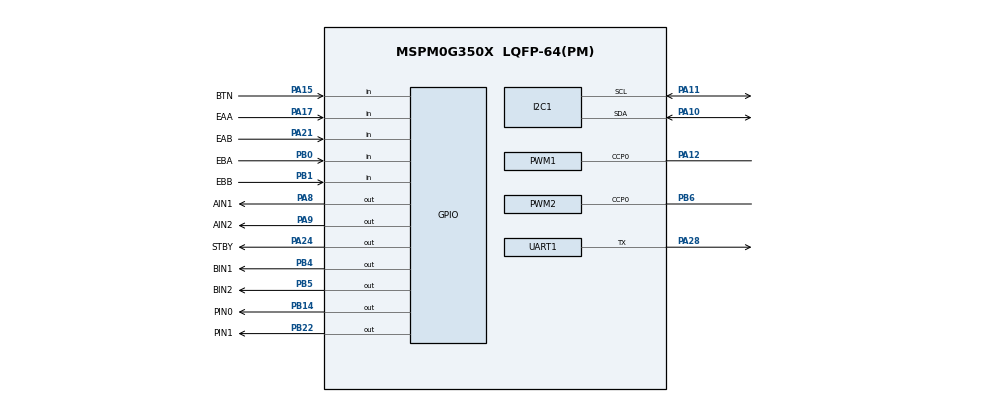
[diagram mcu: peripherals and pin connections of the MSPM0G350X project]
/**
 * @cliArgs --device "MSPM0G350X" --part "Default" --package "LQFP-64(PM)" --product "mspm0_sdk@2.10.00.04"
 * @versions {"tool":"1.26.2+4477"}
 */

/**
 * Import the modules used in this configuration.
 */
const ADC12  = scripting.addModule("/ti/driverlib/ADC12", {}, false);
const ADC121 = ADC12.addInstance();
const GPIO   = scripting.addModule("/ti/driverlib/GPIO", {}, false);
const GPIO1  = GPIO.addInstance();
const GPIO2  = GPIO.addInstance();
const GPIO3  = GPIO.addInstance();
const GPIO4  = GPIO.addInstance();

const I2C    = scripting.addModule("/ti/driverlib/I2C", {}, false);
const I2C1   = I2C.addInstance();
const PWM    = scripting.addModule("/ti/driverlib/PWM", {}, false);
const PWM1   = PWM.addInstance();
const PWM2   = PWM.addInstance();
const SYSCTL = scripting.addModule("/ti/driverlib/SYSCTL");
const UART   = scripting.addModule("/ti/driverlib/UART", {}, false);
const UART1  = UART.addInstance();
const VREF   = scripting.addModule("/ti/driverlib/VREF");

/**
 * Write custom configuration values to the imported modules.
 */
const divider9       = system.clockTree["UDIV"];
divider9.divideValue = 2;

const multiplier2         = system.clockTree["PLL_QDIV"];
multiplier2.multiplyValue = 4;

const mux8       = system.clockTree["HSCLKMUX"];
mux8.inputSelect = "HSCLKMUX_SYSPLL0";

ADC121.$name                      = "ADC12_0";
ADC121.repeatMode                 = true;
ADC121.adcMem0vref                = "VREF";
ADC121.adcMem0chansel             = "DL_ADC12_INPUT_CHAN_1";
ADC121.peripheral.$assign         = "ADC1";
ADC121.peripheral.adcPin1.$assign = "PA16";
ADC121.adcPin1Config.$name        = "ti_driverlib_gpio_GPIOPinGeneric4";

const Board = scripting.addModule("/ti/driverlib/Board", {}, false);

GPIO1.$name                         = "LED";
GPIO1.associatedPins.create(2);
GPIO1.associatedPins[0].$name       = "PIN0";
GPIO1.associatedPins[0].pin.$assign = "PB14";
GPIO1.associatedPins[1].$name       = "PIN1";
GPIO1.associatedPins[1].pin.$assign = "PB22";

GPIO2.$name                              = "DC_MOTOR_1";
GPIO2.associatedPins.create(5);
GPIO2.associatedPins[0].$name            = "AIN1";
GPIO2.associatedPins[0].pin.$assign      = "PA8";
GPIO2.associatedPins[1].$name            = "AIN2";
GPIO2.associatedPins[1].pin.$assign      = "PA9";
GPIO2.associatedPins[2].$name            = "STBY";
GPIO2.associatedPins[2].pin.$assign      = "PA24";
GPIO2.associatedPins[3].$name            = "EAA";
GPIO2.associatedPins[3].direction        = "INPUT";
GPIO2.associatedPins[3].interruptEn      = true;
GPIO2.associatedPins[3].polarity         = "RISE";
GPIO2.associatedPins[3].internalResistor = "PULL_UP";
GPIO2.associatedPins[3].pin.$assign      = "PA17";
GPIO2.associatedPins[4].$name            = "EAB";
GPIO2.associatedPins[4].direction        = "INPUT";
GPIO2.associatedPins[4].interruptEn      = true;
GPIO2.associatedPins[4].polarity         = "RISE";
GPIO2.associatedPins[4].internalResistor = "PULL_UP";
GPIO2.associatedPins[4].pin.$assign      = "PA21";

GPIO3.$name                              = "DC_MOTOR_2";
GPIO3.associatedPins.create(4);
GPIO3.associatedPins[0].$name            = "BIN1";
GPIO3.associatedPins[0].pin.$assign      = "PB4";
GPIO3.associatedPins[1].$name            = "BIN2";
GPIO3.associatedPins[1].pin.$assign      = "PB5";
GPIO3.associatedPins[2].$name            = "EBA";
GPIO3.associatedPins[2].polarity         = "RISE";
GPIO3.associatedPins[2].direction        = "INPUT";
GPIO3.associatedPins[2].interruptEn      = true;
GPIO3.associatedPins[2].internalResistor = "PULL_UP";
GPIO3.associatedPins[2].pin.$assign      = "PB0";
GPIO3.associatedPins[3].$name            = "EBB";
GPIO3.associatedPins[3].direction        = "INPUT";
GPIO3.associatedPins[3].polarity         = "RISE";
GPIO3.associatedPins[3].interruptEn      = true;
GPIO3.associatedPins[3].internalResistor = "PULL_UP";
GPIO3.associatedPins[3].pin.$assign      = "PB1";

GPIO4.$name                              = "BUTTON";
GPIO4.associatedPins[0].$name            = "BTN";
GPIO4.associatedPins[0].internalResistor = "PULL_UP";
GPIO4.associatedPins[0].direction        = "INPUT";
GPIO4.associatedPins[0].pin.$assign      = "PA15";

I2C1.$name                             = "OLED";
I2C1.advDigitalGlitchFilter            = "CLOCKS_1";
I2C1.advControllerRXFIFOTRIG           = "BYTES_8";
I2C1.advControllerTXFIFOTRIG           = "BYTES_7";
I2C1.enableDMAEvent1                   = false;
I2C1.enableDMAEvent2                   = false;
I2C1.basicEnableController             = true;
I2C1.peripheral.$assign                = "I2C1";
I2C1.peripheral.sdaPin.$assign         = "PA10";
I2C1.peripheral.sclPin.$assign         = "PA11";
I2C1.sdaPinConfig.hideOutputInversion  = scripting.forceWrite(false);
I2C1.sdaPinConfig.onlyInternalResistor = scripting.forceWrite(false);
I2C1.sdaPinConfig.passedPeripheralType = scripting.forceWrite("Digital");
I2C1.sdaPinConfig.$name                = "ti_driverlib_gpio_GPIOPinGeneric0";
I2C1.sdaPinConfig.enableConfig         = true;
I2C1.sdaPinConfig.internalResistor     = "PULL_UP";
I2C1.sclPinConfig.hideOutputInversion  = scripting.forceWrite(false);
I2C1.sclPinConfig.onlyInternalResistor = scripting.forceWrite(false);
I2C1.sclPinConfig.passedPeripheralType = scripting.forceWrite("Digital");
I2C1.sclPinConfig.$name                = "ti_driverlib_gpio_GPIOPinGeneric1";
I2C1.sclPinConfig.enableConfig         = true;
I2C1.sclPinConfig.internalResistor     = "PULL_UP";

PWM1.$name                              = "PWMA";
PWM1.timerStartTimer                    = true;
PWM1.ccIndex                            = [0];
PWM1.timerCount                         = 4000;
PWM1.pwmMode                            = "EDGE_ALIGN_UP";
PWM1.clockDivider                       = 2;
PWM1.PWM_CHANNEL_0.$name                = "ti_driverlib_pwm_PWMTimerCC1";
PWM1.ccp0PinConfig.direction            = scripting.forceWrite("OUTPUT");
PWM1.ccp0PinConfig.hideOutputInversion  = scripting.forceWrite(false);
PWM1.ccp0PinConfig.onlyInternalResistor = scripting.forceWrite(false);
PWM1.ccp0PinConfig.passedPeripheralType = scripting.forceWrite("Digital");
PWM1.ccp0PinConfig.$name                = "ti_driverlib_gpio_GPIOPinGeneric6";
PWM1.peripheral.$assign                 = "TIMG0";
PWM1.peripheral.ccp0Pin.$assign         = "PA12";

PWM2.timerStartTimer                    = true;
PWM2.timerCount                         = 4000;
PWM2.pwmMode                            = "EDGE_ALIGN_UP";
PWM2.$name                              = "PWMB";
PWM2.ccIndex                            = [0];
PWM2.clockDivider                       = 2;
PWM2.PWM_CHANNEL_0.$name                = "ti_driverlib_pwm_PWMTimerCC4";
PWM2.ccp0PinConfig.direction            = scripting.forceWrite("OUTPUT");
PWM2.ccp0PinConfig.hideOutputInversion  = scripting.forceWrite(false);
PWM2.ccp0PinConfig.onlyInternalResistor = scripting.forceWrite(false);
PWM2.ccp0PinConfig.passedPeripheralType = scripting.forceWrite("Digital");
PWM2.ccp0PinConfig.$name                = "ti_driverlib_gpio_GPIOPinGeneric10";
PWM2.peripheral.$assign                 = "TIMG6";
PWM2.peripheral.ccp0Pin.$assign         = "PB6";

SYSCTL.forceDefaultClkConfig = true;
SYSCTL.clockTreeEn           = true;

UART1.$name                            = "PRINT";
UART1.targetBaudRate                   = 115200;
UART1.enabledInterrupts                = ["RX"];
UART1.direction                        = "TX";
UART1.txPinConfig.direction            = scripting.forceWrite("OUTPUT");
UART1.txPinConfig.hideOutputInversion  = scripting.forceWrite(false);
UART1.txPinConfig.onlyInternalResistor = scripting.forceWrite(false);
UART1.txPinConfig.passedPeripheralType = scripting.forceWrite("Digital");
UART1.txPinConfig.$name                = "ti_driverlib_gpio_GPIOPinGeneric2";
UART1.peripheral.txPin.$assign         = "PA28";

VREF.basicIntVolt           = "DL_VREF_BUFCONFIG_OUTPUT_2_5V";
VREF.vrefPosPinConfig.$name = "ti_driverlib_gpio_GPIOPinGeneric5";

/**
 * Pinmux solution for unlocked pins/peripherals. This ensures that minor changes to the automatic solver in a future
 * version of the tool will not impact the pinmux you originally saw.  These lines can be completely deleted in order to
 * re-solve from scratch.
 */
Board.peripheral.$suggestSolution           = "DEBUGSS";
Board.peripheral.swclkPin.$suggestSolution  = "PA20";
Board.peripheral.swdioPin.$suggestSolution  = "PA19";
UART1.peripheral.$suggestSolution           = "UART0";
VREF.peripheral.$suggestSolution            = "VREF";
VREF.peripheral.vrefPosPin.$suggestSolution = "PA23";
